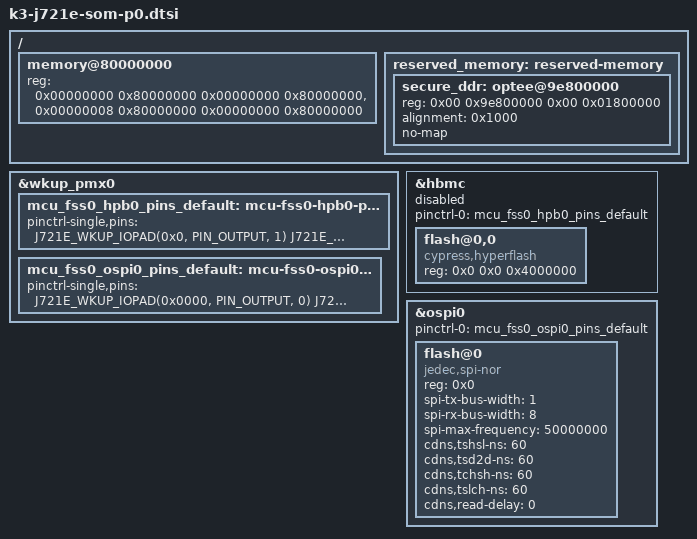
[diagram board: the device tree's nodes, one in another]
// SPDX-License-Identifier: GPL-2.0
/*
 * Copyright (C) 2019 Texas Instruments Incorporated - http://www.ti.com/
 */

/dts-v1/;

#include "k3-j721e.dtsi"

/ {
	memory@80000000 {
		device_type = "memory";
		/* 4G RAM */
		reg = <0x00000000 0x80000000 0x00000000 0x80000000>,
		      <0x00000008 0x80000000 0x00000000 0x80000000>;
	};

	reserved_memory: reserved-memory {
		#address-cells = <2>;
		#size-cells = <2>;
		ranges;

		secure_ddr: optee@9e800000 {
			reg = <0x00 0x9e800000 0x00 0x01800000>;
			alignment = <0x1000>;
			no-map;
		};
	};
};

&wkup_pmx0 {
	mcu_fss0_hpb0_pins_default: mcu-fss0-hpb0-pins-default {
		pinctrl-single,pins = <
			J721E_WKUP_IOPAD(0x0, PIN_OUTPUT, 1) /* (E20) MCU_OSPI0_CLK.MCU_HYPERBUS0_CK */
			J721E_WKUP_IOPAD(0x4, PIN_OUTPUT, 1) /* (C21) MCU_OSPI0_LBCLKO.MCU_HYPERBUS0_CKn */
			J721E_WKUP_IOPAD(0x2c, PIN_OUTPUT, 1) /* (F19) MCU_OSPI0_CSn0.MCU_HYPERBUS0_CSn0 */
			J721E_WKUP_IOPAD(0x54, PIN_OUTPUT, 3) /* (E22) MCU_OSPI1_CSn1.MCU_HYPERBUS0_CSn1 */
			J721E_WKUP_IOPAD(0x30, PIN_OUTPUT, 1) /* (E19) MCU_OSPI0_CSn1.MCU_HYPERBUS0_RESETn */
			J721E_WKUP_IOPAD(0x8, PIN_INPUT, 1) /* (D21) MCU_OSPI0_DQS.MCU_HYPERBUS0_RWDS */
			J721E_WKUP_IOPAD(0xc, PIN_INPUT, 1) /* (D20) MCU_OSPI0_D0.MCU_HYPERBUS0_DQ0 */
			J721E_WKUP_IOPAD(0x10, PIN_INPUT, 1) /* (G19) MCU_OSPI0_D1.MCU_HYPERBUS0_DQ1 */
			J721E_WKUP_IOPAD(0x14, PIN_INPUT, 1) /* (G20) MCU_OSPI0_D2.MCU_HYPERBUS0_DQ2 */
			J721E_WKUP_IOPAD(0x18, PIN_INPUT, 1) /* (F20) MCU_OSPI0_D3.MCU_HYPERBUS0_DQ3 */
			J721E_WKUP_IOPAD(0x1c, PIN_INPUT, 1) /* (F21) MCU_OSPI0_D4.MCU_HYPERBUS0_DQ4 */
			J721E_WKUP_IOPAD(0x20, PIN_INPUT, 1) /* (E21) MCU_OSPI0_D5.MCU_HYPERBUS0_DQ5 */
			J721E_WKUP_IOPAD(0x24, PIN_INPUT, 1) /* (B22) MCU_OSPI0_D6.MCU_HYPERBUS0_DQ6 */
			J721E_WKUP_IOPAD(0x28, PIN_INPUT, 1) /* (G21) MCU_OSPI0_D7.MCU_HYPERBUS0_DQ7 */
		>;
	};

	mcu_fss0_ospi0_pins_default: mcu-fss0-ospi0-pins-default {
		pinctrl-single,pins = <
			J721E_WKUP_IOPAD(0x0000, PIN_OUTPUT, 0) /* MCU_OSPI0_CLK */
			J721E_WKUP_IOPAD(0x0008, PIN_INPUT, 0)  /* MCU_OSPI0_DQS */
			J721E_WKUP_IOPAD(0x000c, PIN_INPUT, 0)  /* MCU_OSPI0_D0 */
			J721E_WKUP_IOPAD(0x0010, PIN_INPUT, 0)  /* MCU_OSPI0_D1 */
			J721E_WKUP_IOPAD(0x0014, PIN_INPUT, 0)  /* MCU_OSPI0_D2 */
			J721E_WKUP_IOPAD(0x0018, PIN_INPUT, 0)  /* MCU_OSPI0_D3 */
			J721E_WKUP_IOPAD(0x001c, PIN_INPUT, 0)  /* MCU_OSPI0_D4 */
			J721E_WKUP_IOPAD(0x0020, PIN_INPUT, 0)  /* MCU_OSPI0_D5 */
			J721E_WKUP_IOPAD(0x0024, PIN_INPUT, 0)  /* MCU_OSPI0_D6 */
			J721E_WKUP_IOPAD(0x0028, PIN_INPUT, 0)  /* MCU_OSPI0_D7 */
			J721E_WKUP_IOPAD(0x002c, PIN_OUTPUT, 0) /* MCU_OSPI0_CSn0 */
		>;
	};
};

&hbmc {
	status = "disabled";
	pinctrl-names = "default";
	pinctrl-0 = <&mcu_fss0_hpb0_pins_default>;
	ranges = <0x0 0x0 0x5 0x0 0x4000000>, /* 64MB Flash on CS0 */
		 <0x1 0x0 0x5 0x4000000 0x800000>; /* 8MB RAM on CS1 */

	flash@0,0 {
		compatible = "cypress,hyperflash", "cfi-flash";
		reg = <0x0 0x0 0x4000000>;
	};
};

&ospi0 {
	pinctrl-names = "default";
	pinctrl-0 = <&mcu_fss0_ospi0_pins_default>;

	flash@0{
		compatible = "jedec,spi-nor";
		reg = <0x0>;
		spi-tx-bus-width = <1>;
		spi-rx-bus-width = <8>;
		spi-max-frequency = <50000000>;
		cdns,tshsl-ns = <60>;
		cdns,tsd2d-ns = <60>;
		cdns,tchsh-ns = <60>;
		cdns,tslch-ns = <60>;
		cdns,read-delay = <0>;
		#address-cells = <1>;
		#size-cells = <1>;
	};
};
